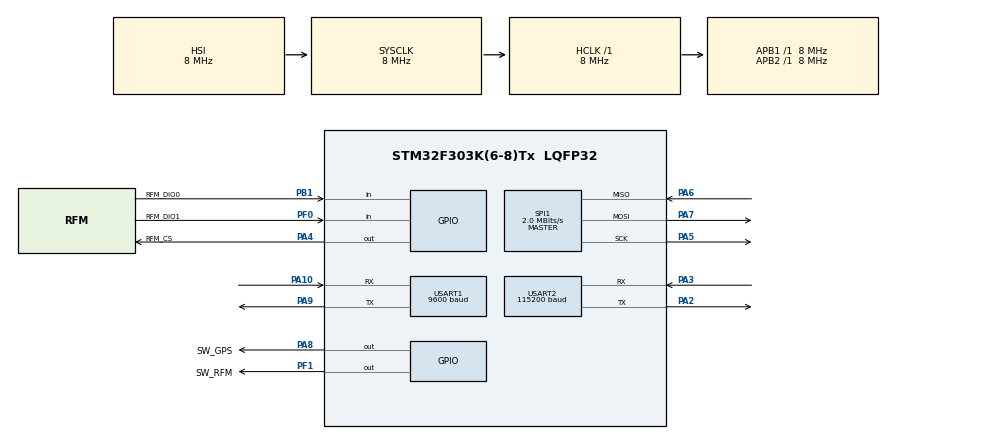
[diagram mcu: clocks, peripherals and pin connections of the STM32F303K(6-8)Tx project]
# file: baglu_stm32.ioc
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Dma.Request0=USART1_RX
Dma.USART1_RX.0.Direction=DMA_PERIPH_TO_MEMORY
Dma.USART1_RX.0.Instance=DMA1_Channel5
Dma.USART1_RX.0.MemDataAlignment=DMA_MDATAALIGN_BYTE
Dma.USART1_RX.0.MemInc=DMA_MINC_ENABLE
Dma.USART1_RX.0.Mode=DMA_NORMAL
Dma.USART1_RX.0.PeriphDataAlignment=DMA_PDATAALIGN_BYTE
Dma.USART1_RX.0.PeriphInc=DMA_PINC_DISABLE
Dma.USART1_RX.0.Priority=DMA_PRIORITY_LOW
Mcu.Family=STM32F3
Mcu.Name=STM32F303K(6-8)Tx
Mcu.Package=LQFP32
NVIC.DMA1_Channel5_IRQn=true\:0\:0\:false\:false\:true\:false
NVIC.PriorityGroup=NVIC_PRIORITYGROUP_4
NVIC.USART1_IRQn=true\:0\:0\:false\:false\:true\:true
PA0.Mode=SYS_WakeUp0
PA0.Signal=SYS_WKUP1
PA10.Mode=Asynchronous
PA10.Signal=USART1_RX
PA2.Mode=Asynchronous
PA2.Signal=USART2_TX
PA3.Mode=Asynchronous
PA3.Signal=USART2_RX
PA4.GPIO_Label=RFM_CS
PA4.PinState=GPIO_PIN_SET
PA4.Signal=GPIO_Output
PA5.Mode=Full_Duplex_Master
PA5.Signal=SPI1_SCK
PA6.Mode=Full_Duplex_Master
PA6.Signal=SPI1_MISO
PA7.Mode=Full_Duplex_Master
PA7.Signal=SPI1_MOSI
PA8.GPIO_Label=SW_GPS
PA8.Signal=GPIO_Output
PA9.Mode=Asynchronous
PA9.Signal=USART1_TX
PB1.GPIO_Label=RFM_DIO0
PB1.Signal=GPIO_Input
PF0\ /\ OSC_IN.GPIO_Label=RFM_DIO1
PF0\ /\ OSC_IN.Signal=GPIO_Input
PF1\ /\ OSC_OUT.GPIO_Label=SW_RFM
PF1\ /\ OSC_OUT.PinState=GPIO_PIN_RESET
PF1\ /\ OSC_OUT.Signal=GPIO_Output
ProjectManager.HeapSize=0x200
ProjectManager.StackSize=0x400
ProjectManager.TargetToolchain=Makefile
RCC.AHBFreq_Value=8000000
RCC.APB1Freq_Value=8000000
RCC.APB1TimFreq_Value=8000000
RCC.APB2Freq_Value=8000000
RCC.APB2TimFreq_Value=8000000
RCC.CortexFreq_Value=8000000
RCC.HCLKFreq_Value=8000000
RCC.HSE_VALUE=8000000
RCC.HSI_VALUE=8000000
RCC.SYSCLKFreq_VALUE=8000000
SPI1.BaudRatePrescaler=SPI_BAUDRATEPRESCALER_4
SPI1.CalculateBaudRate=2.0 MBits/s
SPI1.DataSize=SPI_DATASIZE_8BIT
SPI1.Direction=SPI_DIRECTION_2LINES
SPI1.Mode=SPI_MODE_MASTER
SPI1.VirtualType=VM_MASTER
USART1.BaudRate=9600
USART1.VirtualMode-Asynchronous=VM_ASYNC
USART2.BaudRate=115200
USART2.VirtualMode-Asynchronous=VM_ASYNC
board=custom

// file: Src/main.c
/**
  ******************************************************************************
  * @file           : main.c
  * @brief          : Main program body
  ******************************************************************************
  ** This notice applies to any and all portions of this file
  * that are not between comment pairs USER CODE BEGIN and
  * USER CODE END. Other portions of this file, whether
  * inserted by the user or by software development tools
  * are owned by their respective copyright owners.
  *
  * COPYRIGHT(c) 2020 STMicroelectronics
  *
  * Redistribution and use in source and binary forms, with or without modification,
  * are permitted provided that the following conditions are met:
  *   1. Redistributions of source code must retain the above copyright notice,
  *      this list of conditions and the following disclaimer.
  *   2. Redistributions in binary form must reproduce the above copyright notice,
  *      this list of conditions and the following disclaimer in the documentation
  *      and/or other materials provided with the distribution.
  *   3. Neither the name of STMicroelectronics nor the names of its contributors
  *      may be used to endorse or promote products derived from this software
  *      without specific prior written permission.
  *
  * THIS SOFTWARE IS PROVIDED BY THE COPYRIGHT HOLDERS AND CONTRIBUTORS "AS IS"
  * AND ANY EXPRESS OR IMPLIED WARRANTIES, INCLUDING, BUT NOT LIMITED TO, THE
  * IMPLIED WARRANTIES OF MERCHANTABILITY AND FITNESS FOR A PARTICULAR PURPOSE ARE
  * DISCLAIMED. IN NO EVENT SHALL THE COPYRIGHT HOLDER OR CONTRIBUTORS BE LIABLE
  * FOR ANY DIRECT, INDIRECT, INCIDENTAL, SPECIAL, EXEMPLARY, OR CONSEQUENTIAL
  * DAMAGES (INCLUDING, BUT NOT LIMITED TO, PROCUREMENT OF SUBSTITUTE GOODS OR
  * SERVICES; LOSS OF USE, DATA, OR PROFITS; OR BUSINESS INTERRUPTION) HOWEVER
  * CAUSED AND ON ANY THEORY OF LIABILITY, WHETHER IN CONTRACT, STRICT LIABILITY,
  * OR TORT (INCLUDING NEGLIGENCE OR OTHERWISE) ARISING IN ANY WAY OUT OF THE USE
  * OF THIS SOFTWARE, EVEN IF ADVISED OF THE POSSIBILITY OF SUCH DAMAGE.
  *
  ******************************************************************************
  */
#include "main.h"
#include "stm32f3xx_hal.h"
#include "dma.h"
#include "spi.h"
#include "usart.h"
#include "gpio.h"

/* USER CODE BEGIN PV */
/* Private variables ---------------------------------------------------------*/

/* USER CODE END PV */

void SystemClock_Config(void);

/* USER CODE BEGIN PFP */
/* Private function prototypes -----------------------------------------------*/

/* USER CODE END PFP */

int main(void)
{

  /* MCU Configuration----------------------------------------------------------*/

  /* Reset of all peripherals, Initializes the Flash interface and the Systick. */
  HAL_Init();

  /* Configure the system clock */
  SystemClock_Config();

  /* Initialize all configured peripherals */
  MX_GPIO_Init();
  MX_DMA_Init();
  MX_USART2_UART_Init();
  MX_SPI1_Init();
  MX_USART1_UART_Init();

  /* Infinite loop */
  /* USER CODE BEGIN WHILE */
  while (1)
  {
    HAL_GPIO_TogglePin(SW_RFM_GPIO_Port, SW_RFM_Pin);
    HAL_GPIO_TogglePin(SW_GPS_GPIO_Port, SW_GPS_Pin);
    HAL_Delay(20000);
    // HAL_Delay(20);
    // debug_printf("I have been awoken..\r\n");
    // /* Disable WKUP pin */
    // PWR->CSR &= PWR_CSR_EWUP1;
    // /* Clear Wake-up flag */
    // __HAL_PWR_CLEAR_FLAG(PWR_FLAG_WU);
    // /* Clear StandBy flag */
    // __HAL_PWR_CLEAR_FLAG(PWR_FLAG_SB);
    // /* enable WKUP pin */
    // PWR->CSR |= PWR_CSR_EWUP1;
    // debug_printf("Got here too..\r\n");
    // HAL_Delay(1000);
    // /* Enter standby mode */
    // HAL_PWR_EnterSTANDBYMode();

  /* USER CODE END WHILE */

  }

}

void SystemClock_Config(void)
{

  RCC_OscInitTypeDef RCC_OscInitStruct;
  RCC_ClkInitTypeDef RCC_ClkInitStruct;
  RCC_PeriphCLKInitTypeDef PeriphClkInit;

    /**Initializes the CPU, AHB and APB busses clocks
    */
  RCC_OscInitStruct.OscillatorType = RCC_OSCILLATORTYPE_HSI;
  RCC_OscInitStruct.HSIState = RCC_HSI_ON;
  RCC_OscInitStruct.HSICalibrationValue = 16;
  RCC_OscInitStruct.PLL.PLLState = RCC_PLL_NONE;
  if (HAL_RCC_OscConfig(&RCC_OscInitStruct) != HAL_OK)
  {
    _Error_Handler(__FILE__, __LINE__);
  }

    /**Initializes the CPU, AHB and APB busses clocks
    */
  RCC_ClkInitStruct.ClockType = RCC_CLOCKTYPE_HCLK|RCC_CLOCKTYPE_SYSCLK
                              |RCC_CLOCKTYPE_PCLK1|RCC_CLOCKTYPE_PCLK2;
  RCC_ClkInitStruct.SYSCLKSource = RCC_SYSCLKSOURCE_HSI;
  RCC_ClkInitStruct.AHBCLKDivider = RCC_SYSCLK_DIV1;
  RCC_ClkInitStruct.APB1CLKDivider = RCC_HCLK_DIV1;
  RCC_ClkInitStruct.APB2CLKDivider = RCC_HCLK_DIV1;

  if (HAL_RCC_ClockConfig(&RCC_ClkInitStruct, FLASH_LATENCY_0) != HAL_OK)
  {
    _Error_Handler(__FILE__, __LINE__);
  }

  PeriphClkInit.PeriphClockSelection = RCC_PERIPHCLK_USART1;
  PeriphClkInit.Usart1ClockSelection = RCC_USART1CLKSOURCE_PCLK1;
  if (HAL_RCCEx_PeriphCLKConfig(&PeriphClkInit) != HAL_OK)
  {
    _Error_Handler(__FILE__, __LINE__);
  }

    /**Configure the Systick interrupt time
    */
  HAL_SYSTICK_Config(HAL_RCC_GetHCLKFreq()/1000);

    /**Configure the Systick
    */
  HAL_SYSTICK_CLKSourceConfig(SYSTICK_CLKSOURCE_HCLK);

  /* SysTick_IRQn interrupt configuration */
  HAL_NVIC_SetPriority(SysTick_IRQn, 0, 0);
}

void _Error_Handler(char *file, int line)
{
  while(1)
  {
  }
}

/************************ (C) COPYRIGHT STMicroelectronics *****END OF FILE****/
